CM_ "IMPORT _toyota_2017.dbc"
CM_ "IMPORT _comma.dbc"

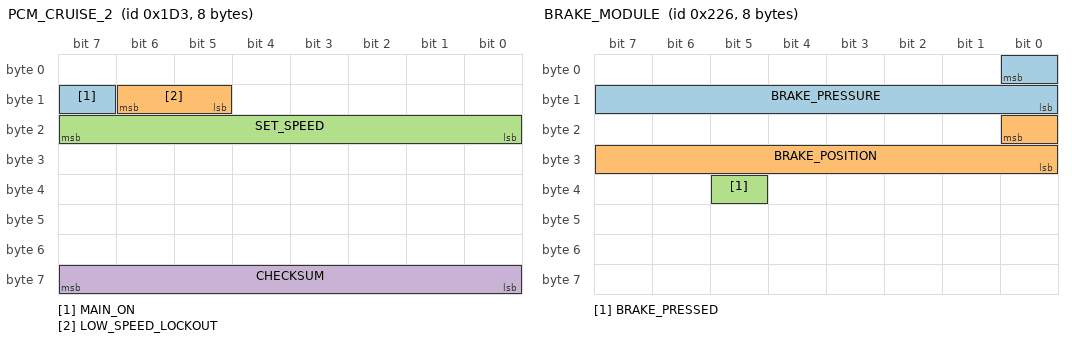
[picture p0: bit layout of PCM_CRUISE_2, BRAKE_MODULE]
BO_ 467 PCM_CRUISE_2: 8 XXX
 SG_ MAIN_ON : 15|1@0+ (1,0) [0|1] "" XXX
 SG_ LOW_SPEED_LOCKOUT : 14|2@0+ (1,0) [0|3] "kph" XXX
 SG_ SET_SPEED : 23|8@0+ (1,0) [0|255] "kph" XXX
 SG_ CHECKSUM : 63|8@0+ (1,0) [0|255] "" XXX

BO_ 550 BRAKE_MODULE: 8 XXX
 SG_ BRAKE_PRESSURE : 0|9@0+ (1,0) [0|511] "" XXX
 SG_ BRAKE_POSITION : 16|9@0+ (1,0) [0|511] "" XXX
 SG_ BRAKE_PRESSED : 37|1@0+ (1,0) [0|1] "" XXX

BO_ 581 GAS_PEDAL: 5 XXX
 SG_ GAS_PEDAL : 23|8@0+ (0.005,0) [0|1] "" XXX

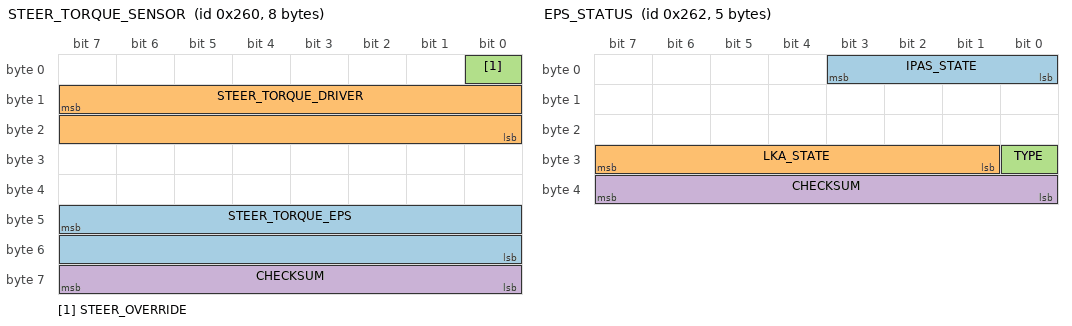
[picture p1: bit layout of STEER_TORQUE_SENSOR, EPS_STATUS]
BO_ 608 STEER_TORQUE_SENSOR: 8 XXX
 SG_ STEER_TORQUE_EPS : 47|16@0- (0.73,0) [-20000|20000] "" XXX
 SG_ STEER_TORQUE_DRIVER : 15|16@0- (1,0) [-32768|32767] "" XXX
 SG_ STEER_OVERRIDE : 0|1@0+ (1,0) [0|1] "" XXX
 SG_ CHECKSUM : 63|8@0+ (1,0) [0|255] "" XXX

BO_ 610 EPS_STATUS: 5 EPS
 SG_ IPAS_STATE : 3|4@0+ (1,0) [0|15] "" XXX
 SG_ LKA_STATE : 31|7@0+ (1,0) [0|127] "" XXX
 SG_ TYPE : 24|1@0+ (1,0) [0|1] "" XXX
 SG_ CHECKSUM : 39|8@0+ (1,0) [0|255] "" XXX

BO_ 643 PRE_COLLISION: 8 XXX

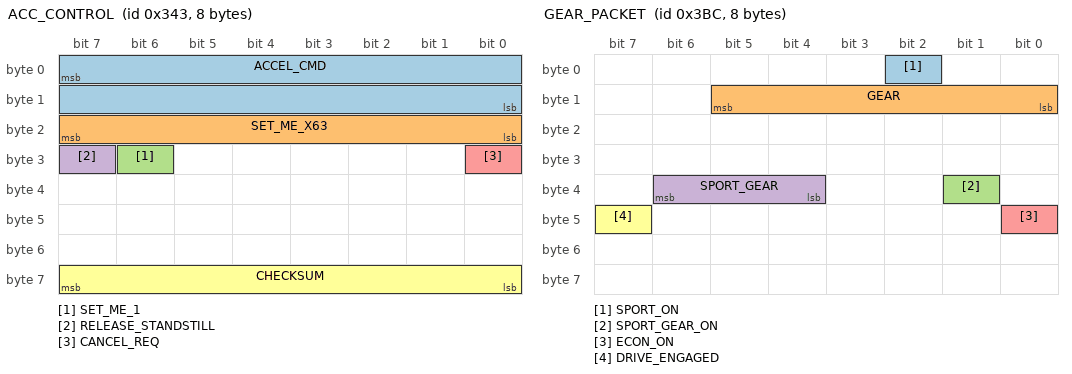
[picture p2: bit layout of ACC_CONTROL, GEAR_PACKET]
BO_ 835 ACC_CONTROL: 8 DSU
 SG_ ACCEL_CMD : 7|16@0- (0.001,0) [-20|20] "m/s2" HCU
 SG_ SET_ME_X63 : 23|8@0+ (1,0) [0|255] "" HCU
 SG_ SET_ME_1 : 30|1@0+ (1,0) [0|1] "" HCU
 SG_ RELEASE_STANDSTILL : 31|1@0+ (1,0) [0|1] "" HCU
 SG_ CANCEL_REQ : 24|1@0+ (1,0) [0|1] "" HCU
 SG_ CHECKSUM : 63|8@0+ (1,0) [0|255] "" XXX

BO_ 956 GEAR_PACKET: 8 XXX
 SG_ SPORT_ON : 2|1@0+ (1,0) [0|1] "" XXX
 SG_ GEAR : 13|6@0+ (1,0) [0|63] "" XXX
 SG_ SPORT_GEAR_ON : 33|1@0+ (1,0) [0|1] "" XXX
 SG_ SPORT_GEAR : 38|3@0+ (1,0) [0|7] "" XXX
 SG_ ECON_ON : 40|1@0+ (1,0) [0|1] "" XXX
 SG_ DRIVE_ENGAGED : 47|1@0+ (1,0) [0|1] "" XXX

CM_ SG_ 467 SET_SPEED "43 kph are shown as 28mph, so conversion isnt perfect";
CM_ SG_ 467 LOW_SPEED_LOCKOUT "in low speed lockout, system would always disengage below 28mph";
CM_ SG_ 550 BRAKE_PRESSURE "seems prop to pedal force";
CM_ SG_ 550 BRAKE_POSITION "seems proportional to pedal displacement, unclear the max value of 0x1c8";
CM_ SG_ 581 GAS_PEDAL "it seems slightly filtered";
CM_ SG_ 610 TYPE "seems 1 on Corolla, 0 on all others";
VAL_ 467 LOW_SPEED_LOCKOUT 2 "low speed locked" 1 "ok";
VAL_ 610 IPAS_STATE 5 "override" 3 "enabled" 1 "disabled";
VAL_ 610 LKA_STATE 25 "temporary_fault" 9 "temporary_fault2" 5 "active" 1 "standby";
VAL_ 956 SPORT_ON 0 "off" 1 "on";
VAL_ 956 GEAR 0 "D" 1 "S" 8 "N" 16 "R" 32 "P";
VAL_ 956 SPORT_GEAR_ON 0 "off" 1 "on";
VAL_ 956 SPORT_GEAR 1 "S1" 2 "S2" 3 "S3" 4 "S4" 5 "S5" 6 "S6";
VAL_ 956 ECON_ON 0 "off" 1 "on";
VAL_ 956 DRIVE_ENGAGED 0 "off" 1 "on";
